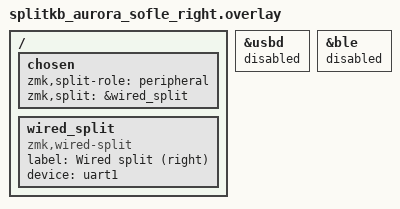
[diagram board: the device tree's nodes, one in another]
/ {
    chosen {
        zmk,split-role = "peripheral";
        zmk,split = &wired_split;
    };

    wired_split: wired_split {
        compatible = "zmk,wired-split";
        label = "Wired split (right)";
        device = <&uart1>;
    };
};

&usbd {
    status = "disabled";
};

&ble {
    status = "disabled";
};
